# EFR32MG24A120F1536GM48 register map
Vendor: Silicon Labs; Series: EFR32; File version: B
Registers are 32-bit, read-write, reset 0x0 unless marked. A register's access mark holds for its fields unless they carry their own. Offsets are from the block's base; [hi:lo] are bit positions; 'fields as' and 'values as' point back to an identical list.

## RFECA0_S — RFECA0_S Registers
Base 0xA8030000
Same registers: RFECA1_S 0xA8034000, RFECA0_NS 0xB8030000, RFECA1_NS 0xB8034000
0x00 IPVERSION ro reset 0x1
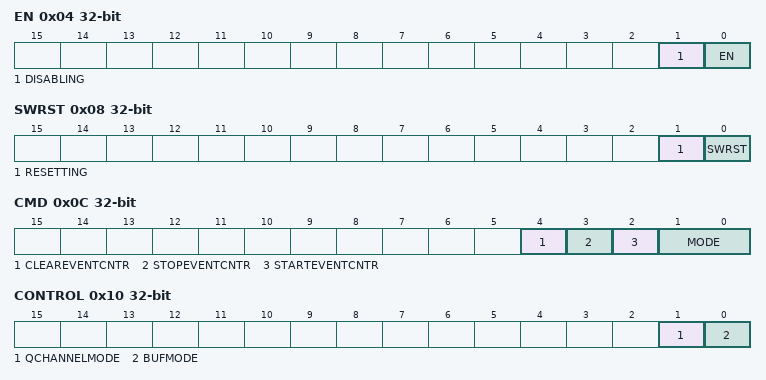
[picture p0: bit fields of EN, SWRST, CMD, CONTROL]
0x04 EN
  [1] DISABLING ro — Disablement Busy Status
  [0] EN — Module Enable
0x08 SWRST
  [1] RESETTING ro — Software Reset Busy Status
  [0] SWRST wo — Software Reset Command
0x0C CMD wo
  [4] CLEAREVENTCNTR — Clear Event Counter
  [3] STOPEVENTCNTR — Stop Event Counter
  [2] STARTEVENTCNTR — Start Event Counter
  [1:0] MODE — Running Mode
    1=DISABLED (Set to make ECA idle); 2=CAPTURE (Set to enable capture mode); 3=PLAYBACK (Set to enable playback mode)
0x10 CONTROL
  [1] QCHANNELMODE
    0=ACCEPT (ECA immediately stops current operation and asserts QACCEPTn after completing the last outstanding DMA bus transaction); 1=DENY (ECA responds to any QREQn request with a QDENY response if ECA is active currenly)
  [0] BUFMODE — Buffer Mode
    0=SINGLE (Single buffer is used); 1=DUAL (Dual buffers are used)
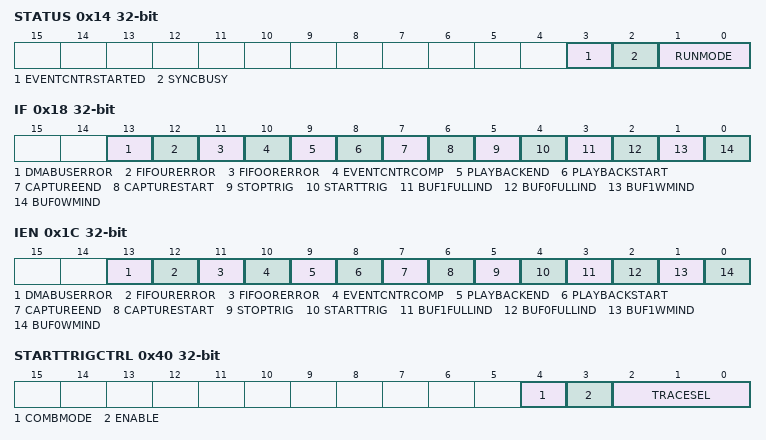
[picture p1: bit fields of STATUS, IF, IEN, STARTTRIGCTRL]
0x14 STATUS ro
  [3] EVENTCNTRSTARTED — Event Counter Started
  [2] SYNCBUSY
  [1:0] RUNMODE
    0=DISABLED (ECA is disabled); 1=CAPTURE (Capture mode is running); 2=PLAYBACK (Playback mode is running)
0x18 IF
  [13] DMABUSERROR
  [12] FIFOURERROR — FIFO Underrun Error
  [11] FIFOORERROR — FIFO Overrun Error
  [10] EVENTCNTRCOMP — Event Counter Compare
  [9] PLAYBACKEND
  [8] PLAYBACKSTART
  [7] CAPTUREEND
  [6] CAPTURESTART
  [5] STOPTRIG — Stop Trigger
  [4] STARTTRIG — Start Trigger
  [3] BUF1FULLIND — BUF1 Full Indication
  [2] BUF0FULLIND — BUF0 Full Indication
  [1] BUF1WMIND — BUF1 Watermark Indication
  [0] BUF0WMIND — BUF0 Watermark Indication
0x1C IEN
  [13] DMABUSERROR — New BitField
  [12] FIFOURERROR — New BitField
  [11] FIFOORERROR — New BitField
  [10] EVENTCNTRCOMP — New BitField
  [9] PLAYBACKEND — New BitField
  [8] PLAYBACKSTART — New BitField
  [7] CAPTUREEND — New BitField
  [6] CAPTURESTART — New BitField
  [5] STOPTRIG — New BitField
  [4] STARTTRIG — New BitField
  [3] BUF1FULLIND — New BitField
  [2] BUF0FULLIND — New BitField
  [1] BUF1WMIND — New BitField
  [0] BUF0WMIND — New BitField
0x20 DMABUSERRORSTATUS ro
  [31:0] ADDR — DMA BUS ERROR ADDRESS
0x24 BUF0_BASE
  [31:0] BASE — Base Address
0x28 BUF0_LIMITOFFSET
  [18:2] OFFSET — Limit Offset
0x2C BUF0_WMOFFSET
  [18:2] OFFSET — Watermark Offset
0x30 BUF1_BASE
  [31:0] BASE — Base Address
0x34 BUF1_LIMITOFFSET
  [18:2] OFFSET — Limit Offset
0x38 BUF1_WMOFFSET
  [18:2] OFFSET — Watermark Offset
0x3C BUFPTRSTATUS ro
  [31:0] STATUS — Buffer Pointer Status
0x40 STARTTRIGCTRL
  [4] COMBMODE — Combination Mode
    0=AND; 1=OR
  [3] ENABLE
  [2:0] TRACESEL — Trace Select
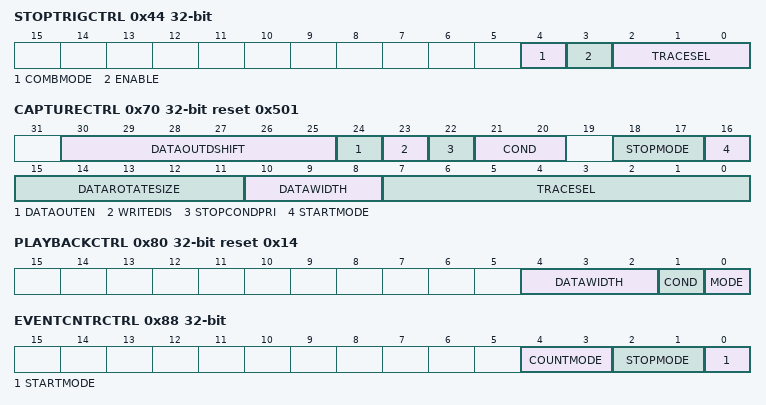
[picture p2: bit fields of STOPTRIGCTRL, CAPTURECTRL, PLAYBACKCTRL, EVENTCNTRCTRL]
0x44 STOPTRIGCTRL
  fields as STARTTRIGCTRL
0x48 STARTTRIGENMASK
  [31:0] ENMASK — Enable Mask
0x4C STARTTRIGREDMASK
  [31:0] REDMASK — Rising Edge Mask
0x50 STARTTRIGFEDMASK
  [31:0] FEDMASK — Falling Edge Mask
0x54 STARTTRIGLVL0MASK
  [31:0] LVL0MASK — Level 0 Mask
0x58 STARTTRIGLVL1MASK
  [31:0] LVL1MASK — Level 1 Mask
0x5C STOPTRIGENMASK
  [31:0] ENMASK — Enable Mask
0x60 STOPTRIGREDMASK
  [31:0] REDMASK — Rising Edge Mask
0x64 STOPTRIGFEDMASK
  [31:0] FEDMASK — Falling Edge Mask
0x68 STOPTRIGLVL0MASK
  [31:0] LVL0MASK — Level 0 Mask
0x6C STOPTRIGLVL1MASK
  [31:0] LVL1MASK — Level 1 Mask
0x70 CAPTURECTRL reset 0x501
  [30:25] DATAOUTDSHIFT — Port Interface Shift
  [24] DATAOUTEN — Port Interface Enable
  [23] WRITEDIS — Write Memory Disable
  [22] STOPCONDPRI — Stop Condition Priority
  [21:20] COND — Condition
    0=TIMED (Capture condition is based on the rate specified in CAPTURERATECTRL register within the active capture window); 1=START_TRIGGER (Capture condition is every start-trigger event in the active capture windo); 2=SLAVE (Capture condition is every cycle when cap_event_in input is high)
  [18:17] STOPMODE
    0=CONTINUOUS (Capture will continue to occur until another mode is configured); 1=BUF_FULL (Capture will stop when the memory buffer is full. In this mode CAPTURESTOPDELAY has no effect); 2=STOP_TRIGGER (Capture will stop when the stop-trigger event occurs or optionally after a CAPTURESTOPDELAY number of cycles/capture-events if configured); 3=STOP_TRIGGER_FULL (Capture stops when either of the following conditions is met (in either of these conditions, CAPTURESTOPDELAY has no effect): BUF_FULL condition or STOP_TRIGGER condition)
  [16] STARTMODE
    0=MANUAL (In this mode, setting CMD.MODE=CAPTURE would start the capture); 1=START_TRIGGER (In this mode, a start-trigger(via STARTTRIGCTRL) would start the capture)
  [15:11] DATAROTATESIZE
  [10:8] DATAWIDTH
    0=BIT1 (1 bit); 1=BIT2 (2 bits); 2=BIT4 (4 bits); 3=BIT8 (8 bits); 4=BIT16 (16 bits); 5=BIT32 (32 bits)
  [7:0] TRACESEL — Trace Select
0x74 CAPTURESTARTDELAY
  [31:0] DELAY — Start Delay
0x78 CAPTURESTOPDELAY
  [31:0] DELAY — Stop Delay
0x7C CAPTURERATECTRL
  [15:0] RATE — Capture Rate
0x80 PLAYBACKCTRL reset 0x14
  [4:2] DATAWIDTH — Playback Data Width
    values as CAPTURECTRL.DATAWIDTH
  [1] COND — Playback Condition
    0=START_TRIGGER (Playback event occurs at every start-trigger event); 1=TIMED (Playback event occurs based on rate defined in PLAYBACL_RATE_CTRL)
  [0] MODE — Playback Mode
    0=SINGLE (Playback starts at BUF0_BASE and stops at BUF1_BASE + BUF1_LIMITOFFSET); 1=LOOP (Playback starts at BUF0_BASE and loops/wraps continuously until CTRL.MODE != PLAYBACK (this can be supported in single or double-buffer modes))
0x84 PLAYBACKRATECTRL
  [15:0] RATE — Playback Rate
0x88 EVENTCNTRCTRL
  [4:3] COUNTMODE
    0=ALWAYS (Increment on every clock cycle); 1=START_TRIGGER (Increment on every start-trigger event); 2=STOP_TRIGGER (Increment on every stop-trigger event); 3=ALL_TRIGGER (Increment on either every start- or stop-trigger event)
  [2:1] STOPMODE
    0=MANUAL (When writing a 1, stops the counter advancing); 1=STOP_TRIGGER (When stop trigger is active, stops the counter advancing); 2=COMPARE (When the count reaches the value programmed in EVENTCNTRCOMPARE, stops the counter advancing)
  [0] STARTMODE
    0=MANUAL (Counting starts as soon as ENABLE=1); 1=START_TRIGGER (Counting starts when the start-trigger event occurs)
0x8C EVENTCNTRCOMPARE
  [31:0] COMPARE — Compare Value
0x90 EVENTCNTRSTATUS ro
  [31:0] STATUS — Event Count Value
